AUTOSAR XML (schema 4-0-3)
standard types defined: Boolean, UInt16, UInt32
package /AUTOSAR_Platform/DataConstrs
  range DC_Boolean: raw 0..1
  range DC_UInt16: raw 0..65535
package /PATAC/MSM/ComponentTypes
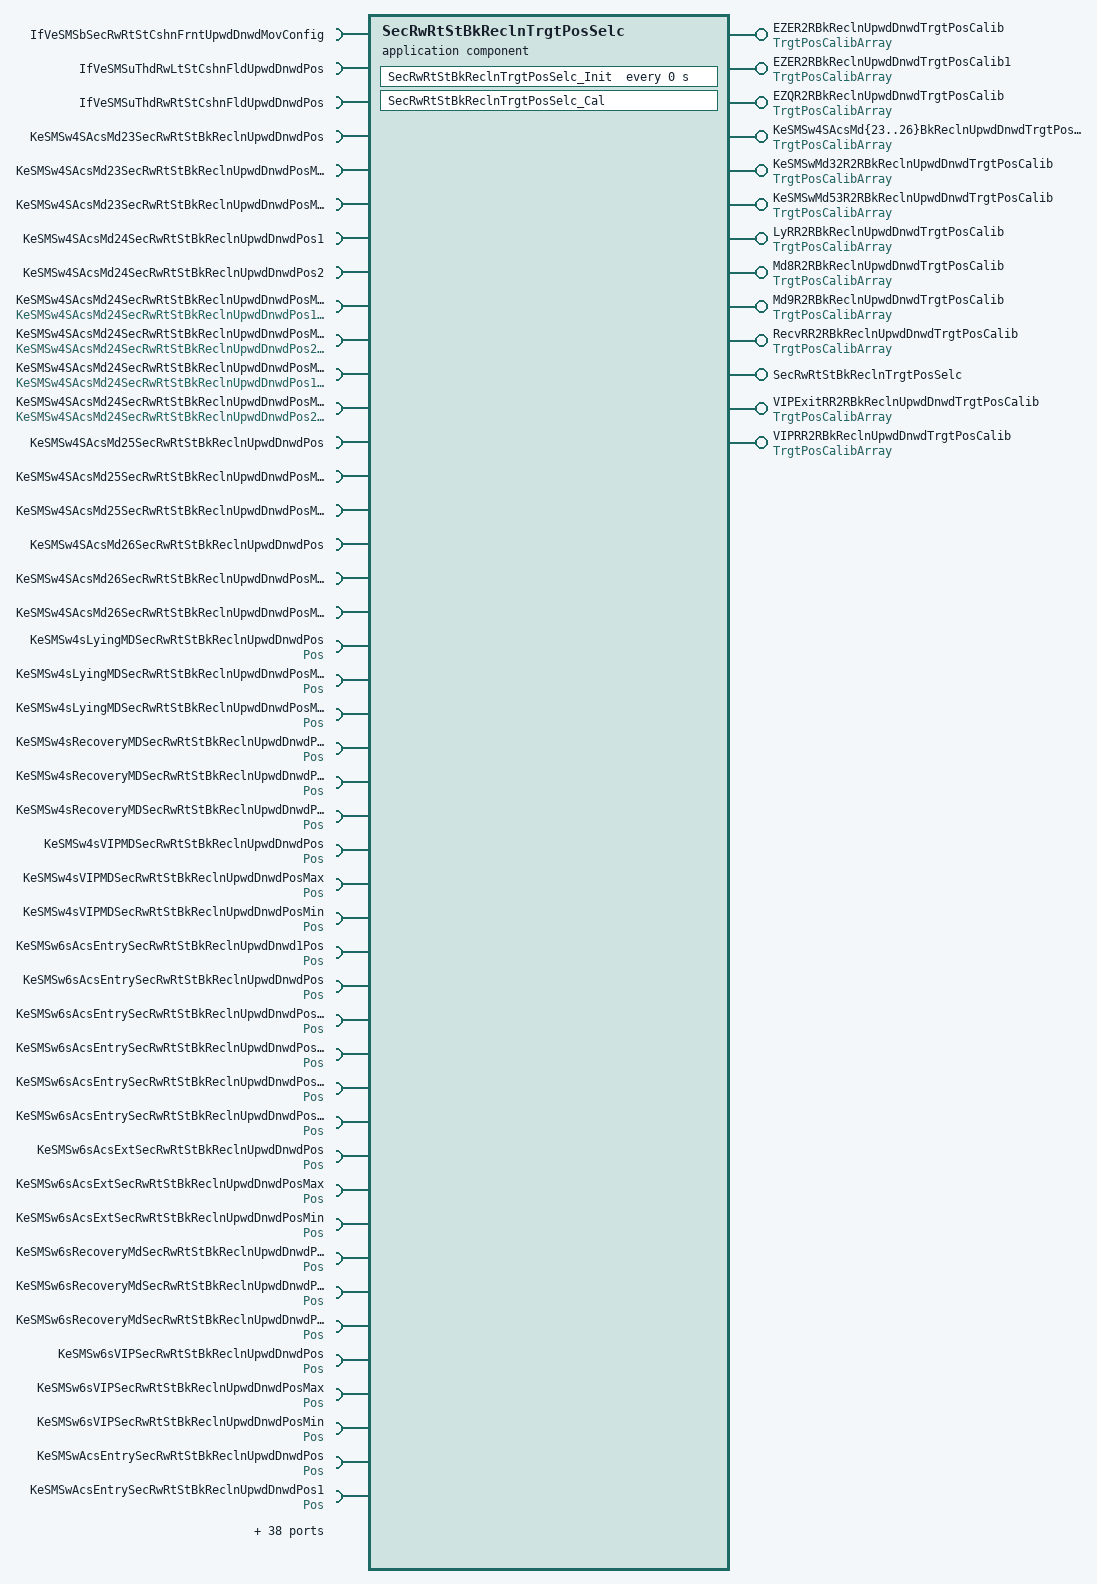
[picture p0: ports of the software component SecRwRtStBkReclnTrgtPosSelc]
  application sw component type SecRwRtStBkReclnTrgtPosSelc
    16 x provide port:
      EZER2RBkReclnUpwdDnwdTrgtPosCalib: nonqueued-sender-com-spec{data-element=TrgtPosArray, init-value=[4095, 4095, 4095]}, provided-interface=TrgtPosCalibArray
      EZER2RBkReclnUpwdDnwdTrgtPosCalib1: nonqueued-sender-com-spec{data-element=TrgtPosArray, init-value=[4095, 4095, 4095]}, provided-interface=TrgtPosCalibArray
      EZQR2RBkReclnUpwdDnwdTrgtPosCalib: nonqueued-sender-com-spec{data-element=TrgtPosArray, init-value=[4095, 4095, 4095]}, provided-interface=TrgtPosCalibArray
      KeSMSw4SAcsMd{23..26}BkReclnUpwdDnwdTrgtPosCalib: nonqueued-sender-com-spec{data-element=TrgtPosArray, init-value=[4095, 4095, 4095]}, provided-interface=TrgtPosCalibArray
      KeSMSwMd32R2RBkReclnUpwdDnwdTrgtPosCalib: nonqueued-sender-com-spec{data-element=TrgtPosArray, init-value=[4095, 4095, 4095]}, provided-interface=TrgtPosCalibArray
      KeSMSwMd53R2RBkReclnUpwdDnwdTrgtPosCalib: nonqueued-sender-com-spec{data-element=TrgtPosArray, init-value=[4095, 4095, 4095]}, provided-interface=TrgtPosCalibArray
      LyRR2RBkReclnUpwdDnwdTrgtPosCalib: nonqueued-sender-com-spec{data-element=TrgtPosArray, init-value=[4095, 4095, 4095]}, provided-interface=TrgtPosCalibArray
      Md8R2RBkReclnUpwdDnwdTrgtPosCalib: nonqueued-sender-com-spec{data-element=TrgtPosArray, init-value=[4095, 4095, 4095]}, provided-interface=TrgtPosCalibArray
      Md9R2RBkReclnUpwdDnwdTrgtPosCalib: nonqueued-sender-com-spec{data-element=TrgtPosArray, init-value=[4095, 4095, 4095]}, provided-interface=TrgtPosCalibArray
      RecvRR2RBkReclnUpwdDnwdTrgtPosCalib: nonqueued-sender-com-spec{data-element=TrgtPosArray, init-value=[4095, 4095, 4095]}, provided-interface=TrgtPosCalibArray
      SecRwRtStBkReclnTrgtPosSelc: server-com-spec{operation=Cal, queue-length=1}, provided-interface=SecRwRtStBkReclnTrgtPosSelc
      VIPExitRR2RBkReclnUpwdDnwdTrgtPosCalib: nonqueued-sender-com-spec{data-element=TrgtPosArray, init-value=[4095, 4095, 4095]}, provided-interface=TrgtPosCalibArray
      VIPRR2RBkReclnUpwdDnwdTrgtPosCalib: nonqueued-sender-com-spec{data-element=TrgtPosArray, init-value=[4095, 4095, 4095]}, provided-interface=TrgtPosCalibArray
    82 x require port:
      IfVeSMSbSecRwRtStCshnFrntUpwdDnwdMovConfig: nonqueued-receiver-com-spec{data-element=IfVeSMSbSecRwRtStCshnFrntUpwdDnwdMovConfig/Val, filter=data-filter-type=ALWAYS, init-value=0}, required-interface=IfVeSMSbSecRwRtStCshnFrntUpwdDnwdMovConfig
      IfVeSMSuThdRwLtStCshnFldUpwdDnwdPos: nonqueued-receiver-com-spec{data-element=IfVeSMSuThdRwLtStCshnFldUpwdDnwdPos/Val, filter=data-filter-type=ALWAYS, init-value=0}, required-interface=IfVeSMSuThdRwLtStCshnFldUpwdDnwdPos
      IfVeSMSuThdRwRtStCshnFldUpwdDnwdPos: nonqueued-receiver-com-spec{data-element=IfVeSMSuThdRwRtStCshnFldUpwdDnwdPos/Val, filter=data-filter-type=ALWAYS, init-value=0}, required-interface=IfVeSMSuThdRwRtStCshnFldUpwdDnwdPos
      KeSMSw4SAcsMd23SecRwRtStBkReclnUpwdDnwdPos: parameter-require-com-spec{init-value=0, parameter=KeSMSw4SAcsMd23SecRwRtStBkReclnUpwdDnwdPos/Val}, required-interface=KeSMSw4SAcsMd23SecRwRtStBkReclnUpwdDnwdPos
      KeSMSw4SAcsMd23SecRwRtStBkReclnUpwdDnwdPosMax: parameter-require-com-spec{init-value=0, parameter=KeSMSw4SAcsMd23SecRwRtStBkReclnUpwdDnwdPosMax/Val}, required-interface=KeSMSw4SAcsMd23SecRwRtStBkReclnUpwdDnwdPosMax
      KeSMSw4SAcsMd23SecRwRtStBkReclnUpwdDnwdPosMin: parameter-require-com-spec{init-value=0, parameter=KeSMSw4SAcsMd23SecRwRtStBkReclnUpwdDnwdPosMin/Val}, required-interface=KeSMSw4SAcsMd23SecRwRtStBkReclnUpwdDnwdPosMin
      KeSMSw4SAcsMd24SecRwRtStBkReclnUpwdDnwdPos1: parameter-require-com-spec{init-value=0, parameter=KeSMSw4SAcsMd24SecRwRtStBkReclnUpwdDnwdPos1/Val}, required-interface=KeSMSw4SAcsMd24SecRwRtStBkReclnUpwdDnwdPos1
      KeSMSw4SAcsMd24SecRwRtStBkReclnUpwdDnwdPos2: parameter-require-com-spec{init-value=0, parameter=KeSMSw4SAcsMd24SecRwRtStBkReclnUpwdDnwdPos2/Val}, required-interface=KeSMSw4SAcsMd24SecRwRtStBkReclnUpwdDnwdPos2
      KeSMSw4SAcsMd24SecRwRtStBkReclnUpwdDnwdPosMax1: parameter-require-com-spec{init-value=0, parameter=KeSMSw4SAcsMd24SecRwRtStBkReclnUpwdDnwdPos1Max/Val}, required-interface=KeSMSw4SAcsMd24SecRwRtStBkReclnUpwdDnwdPos1Max
      KeSMSw4SAcsMd24SecRwRtStBkReclnUpwdDnwdPosMax2: parameter-require-com-spec{init-value=0, parameter=KeSMSw4SAcsMd24SecRwRtStBkReclnUpwdDnwdPos2Max/Val}, required-interface=KeSMSw4SAcsMd24SecRwRtStBkReclnUpwdDnwdPos2Max
      KeSMSw4SAcsMd24SecRwRtStBkReclnUpwdDnwdPosMin1: parameter-require-com-spec{init-value=0, parameter=KeSMSw4SAcsMd24SecRwRtStBkReclnUpwdDnwdPos1Min/Val}, required-interface=KeSMSw4SAcsMd24SecRwRtStBkReclnUpwdDnwdPos1Min
      KeSMSw4SAcsMd24SecRwRtStBkReclnUpwdDnwdPosMin2: parameter-require-com-spec{init-value=0, parameter=KeSMSw4SAcsMd24SecRwRtStBkReclnUpwdDnwdPos2Min/Val}, required-interface=KeSMSw4SAcsMd24SecRwRtStBkReclnUpwdDnwdPos2Min
      KeSMSw4SAcsMd25SecRwRtStBkReclnUpwdDnwdPos: parameter-require-com-spec{init-value=0, parameter=KeSMSw4SAcsMd25SecRwRtStBkReclnUpwdDnwdPos/Val}, required-interface=KeSMSw4SAcsMd25SecRwRtStBkReclnUpwdDnwdPos
      KeSMSw4SAcsMd25SecRwRtStBkReclnUpwdDnwdPosMax: parameter-require-com-spec{init-value=0, parameter=KeSMSw4SAcsMd25SecRwRtStBkReclnUpwdDnwdPosMax/Val}, required-interface=KeSMSw4SAcsMd25SecRwRtStBkReclnUpwdDnwdPosMax
      KeSMSw4SAcsMd25SecRwRtStBkReclnUpwdDnwdPosMin: parameter-require-com-spec{init-value=0, parameter=KeSMSw4SAcsMd25SecRwRtStBkReclnUpwdDnwdPosMin/Val}, required-interface=KeSMSw4SAcsMd25SecRwRtStBkReclnUpwdDnwdPosMin
      KeSMSw4SAcsMd26SecRwRtStBkReclnUpwdDnwdPos: parameter-require-com-spec{init-value=0, parameter=KeSMSw4SAcsMd26SecRwRtStBkReclnUpwdDnwdPos/Val}, required-interface=KeSMSw4SAcsMd26SecRwRtStBkReclnUpwdDnwdPos
      KeSMSw4SAcsMd26SecRwRtStBkReclnUpwdDnwdPosMax: parameter-require-com-spec{init-value=0, parameter=KeSMSw4SAcsMd26SecRwRtStBkReclnUpwdDnwdPosMax/Val}, required-interface=KeSMSw4SAcsMd26SecRwRtStBkReclnUpwdDnwdPosMax
      KeSMSw4SAcsMd26SecRwRtStBkReclnUpwdDnwdPosMin: parameter-require-com-spec{init-value=0, parameter=KeSMSw4SAcsMd26SecRwRtStBkReclnUpwdDnwdPosMin/Val}, required-interface=KeSMSw4SAcsMd26SecRwRtStBkReclnUpwdDnwdPosMin
      KeSMSw4sLyingMDSecRwRtStBkReclnUpwdDnwdPos: parameter-require-com-spec{init-value=0, parameter=Pos/Val}, required-interface=Pos
      KeSMSw4sLyingMDSecRwRtStBkReclnUpwdDnwdPosMax: parameter-require-com-spec{init-value=0, parameter=Pos/Val}, required-interface=Pos
      KeSMSw4sLyingMDSecRwRtStBkReclnUpwdDnwdPosMin: parameter-require-com-spec{init-value=0, parameter=Pos/Val}, required-interface=Pos
      KeSMSw4sRecoveryMDSecRwRtStBkReclnUpwdDnwdPos: parameter-require-com-spec{init-value=0, parameter=Pos/Val}, required-interface=Pos
      KeSMSw4sRecoveryMDSecRwRtStBkReclnUpwdDnwdPosMax: parameter-require-com-spec{init-value=0, parameter=Pos/Val}, required-interface=Pos
      KeSMSw4sRecoveryMDSecRwRtStBkReclnUpwdDnwdPosMin: parameter-require-com-spec{init-value=0, parameter=Pos/Val}, required-interface=Pos
      KeSMSw4sVIPMDSecRwRtStBkReclnUpwdDnwdPos: parameter-require-com-spec{init-value=0, parameter=Pos/Val}, required-interface=Pos
      KeSMSw4sVIPMDSecRwRtStBkReclnUpwdDnwdPosMax: parameter-require-com-spec{init-value=0, parameter=Pos/Val}, required-interface=Pos
      KeSMSw4sVIPMDSecRwRtStBkReclnUpwdDnwdPosMin: parameter-require-com-spec{init-value=0, parameter=Pos/Val}, required-interface=Pos
      KeSMSw6sAcsEntrySecRwRtStBkReclnUpwdDnwd1Pos: parameter-require-com-spec{init-value=1280, parameter=Pos/Val}, required-interface=Pos
      KeSMSw6sAcsEntrySecRwRtStBkReclnUpwdDnwdPos: parameter-require-com-spec{init-value=1280, parameter=Pos/Val}, required-interface=Pos
      KeSMSw6sAcsEntrySecRwRtStBkReclnUpwdDnwdPos1Max: parameter-require-com-spec{init-value=1280, parameter=Pos/Val}, required-interface=Pos
      KeSMSw6sAcsEntrySecRwRtStBkReclnUpwdDnwdPos1Min: parameter-require-com-spec{init-value=0, parameter=Pos/Val}, required-interface=Pos
      KeSMSw6sAcsEntrySecRwRtStBkReclnUpwdDnwdPosMax: parameter-require-com-spec{init-value=1280, parameter=Pos/Val}, required-interface=Pos
      KeSMSw6sAcsEntrySecRwRtStBkReclnUpwdDnwdPosMin: parameter-require-com-spec{init-value=0, parameter=Pos/Val}, required-interface=Pos
      KeSMSw6sAcsExtSecRwRtStBkReclnUpwdDnwdPos: parameter-require-com-spec{init-value=1280, parameter=Pos/Val}, required-interface=Pos
      KeSMSw6sAcsExtSecRwRtStBkReclnUpwdDnwdPosMax: parameter-require-com-spec{init-value=1280, parameter=Pos/Val}, required-interface=Pos
      KeSMSw6sAcsExtSecRwRtStBkReclnUpwdDnwdPosMin: parameter-require-com-spec{init-value=0, parameter=Pos/Val}, required-interface=Pos
      KeSMSw6sRecoveryMdSecRwRtStBkReclnUpwdDnwdPos: parameter-require-com-spec{init-value=1268, parameter=Pos/Val}, required-interface=Pos
      KeSMSw6sRecoveryMdSecRwRtStBkReclnUpwdDnwdPosMax: parameter-require-com-spec{init-value=1268, parameter=Pos/Val}, required-interface=Pos
      KeSMSw6sRecoveryMdSecRwRtStBkReclnUpwdDnwdPosMin: parameter-require-com-spec{init-value=0, parameter=Pos/Val}, required-interface=Pos
      KeSMSw6sVIPSecRwRtStBkReclnUpwdDnwdPos: parameter-require-com-spec{init-value=1960, parameter=Pos/Val}, required-interface=Pos
      KeSMSw6sVIPSecRwRtStBkReclnUpwdDnwdPosMax: parameter-require-com-spec{init-value=40, parameter=Pos/Val}, required-interface=Pos
      KeSMSw6sVIPSecRwRtStBkReclnUpwdDnwdPosMin: parameter-require-com-spec{init-value=1960, parameter=Pos/Val}, required-interface=Pos
      KeSMSwAcsEntrySecRwRtStBkReclnUpwdDnwdPos: parameter-require-com-spec{init-value=1280, parameter=Pos/Val}, required-interface=Pos
      KeSMSwAcsEntrySecRwRtStBkReclnUpwdDnwdPos1: parameter-require-com-spec{init-value=1280, parameter=Pos/Val}, required-interface=Pos
      KeSMSwAcsEntrySecRwRtStBkReclnUpwdDnwdPos1Max: parameter-require-com-spec{init-value=1280, parameter=Pos/Val}, required-interface=Pos
      KeSMSwAcsEntrySecRwRtStBkReclnUpwdDnwdPos1Min: parameter-require-com-spec{init-value=0, parameter=Pos/Val}, required-interface=Pos
      KeSMSwAcsEntrySecRwRtStBkReclnUpwdDnwdPosMax: parameter-require-com-spec{init-value=1280, parameter=Pos/Val}, required-interface=Pos
      KeSMSwAcsEntrySecRwRtStBkReclnUpwdDnwdPosMin: parameter-require-com-spec{init-value=0, parameter=Pos/Val}, required-interface=Pos
      KeSMSwAcsExtSecRwRtStBkReclnUpwdDnwdPos: parameter-require-com-spec{init-value=1280, parameter=Pos/Val}, required-interface=Pos
      KeSMSwAcsExtSecRwRtStBkReclnUpwdDnwdPosMax: parameter-require-com-spec{init-value=1280, parameter=Pos/Val}, required-interface=Pos
      KeSMSwAcsExtSecRwRtStBkReclnUpwdDnwdPosMin: parameter-require-com-spec{init-value=0, parameter=Pos/Val}, required-interface=Pos
      KeSMSwAcsMd32SecRwRtStBkReclnUpwdDnwdPos: parameter-require-com-spec{init-value=0, parameter=Pos/Val}, required-interface=Pos
      KeSMSwAcsMd32SecRwRtStBkReclnUpwdDnwdPos1: parameter-require-com-spec{init-value=0, parameter=Pos/Val}, required-interface=Pos
      KeSMSwAcsMd32SecRwRtStBkReclnUpwdDnwdPos1Max: parameter-require-com-spec{init-value=0, parameter=Pos/Val}, required-interface=Pos
      KeSMSwAcsMd32SecRwRtStBkReclnUpwdDnwdPos1Min: parameter-require-com-spec{init-value=0, parameter=Pos/Val}, required-interface=Pos
      KeSMSwAcsMd32SecRwRtStBkReclnUpwdDnwdPosMax: parameter-require-com-spec{init-value=0, parameter=Pos/Val}, required-interface=Pos
      KeSMSwAcsMd32SecRwRtStBkReclnUpwdDnwdPosMin: parameter-require-com-spec{init-value=0, parameter=Pos/Val}, required-interface=Pos
      KeSMSwAcsMd53SecRwRtStBkReclnUpwdDnwdPos: parameter-require-com-spec{init-value=0, parameter=Pos/Val}, required-interface=Pos
      KeSMSwAcsMd53SecRwRtStBkReclnUpwdDnwdPos1: parameter-require-com-spec{init-value=0, parameter=Pos/Val}, required-interface=Pos
      KeSMSwAcsMd53SecRwRtStBkReclnUpwdDnwdPos1Max: parameter-require-com-spec{init-value=0, parameter=Pos/Val}, required-interface=Pos
      KeSMSwAcsMd53SecRwRtStBkReclnUpwdDnwdPos1Min: parameter-require-com-spec{init-value=0, parameter=Pos/Val}, required-interface=Pos
      KeSMSwAcsMd53SecRwRtStBkReclnUpwdDnwdPosMax: parameter-require-com-spec{init-value=0, parameter=Pos/Val}, required-interface=Pos
      KeSMSwAcsMd53SecRwRtStBkReclnUpwdDnwdPosMin: parameter-require-com-spec{init-value=0, parameter=Pos/Val}, required-interface=Pos
      KeSMSwAcsMd8SecRwRtStBkReclnUpwdDnwdPos: parameter-require-com-spec{init-value=0, parameter=Pos/Val}, required-interface=Pos
      KeSMSwAcsMd8SecRwRtStBkReclnUpwdDnwdPosMax: parameter-require-com-spec{init-value=0, parameter=Pos/Val}, required-interface=Pos
      KeSMSwAcsMd8SecRwRtStBkReclnUpwdDnwdPosMin: parameter-require-com-spec{init-value=0, parameter=Pos/Val}, required-interface=Pos
      KeSMSwAcsMd9SecRwRtStBkReclnUpwdDnwdPos: parameter-require-com-spec{init-value=0, parameter=Pos/Val}, required-interface=Pos
      KeSMSwAcsMd9SecRwRtStBkReclnUpwdDnwdPosMax: parameter-require-com-spec{init-value=0, parameter=Pos/Val}, required-interface=Pos
      KeSMSwAcsMd9SecRwRtStBkReclnUpwdDnwdPosMin: parameter-require-com-spec{init-value=0, parameter=Pos/Val}, required-interface=Pos
      KeSMSwRecoveryMdSecRwRtStBkReclnUpwdDnwdPos: parameter-require-com-spec{init-value=1268, parameter=Pos/Val}, required-interface=Pos
      KeSMSwRecoveryMdSecRwRtStBkReclnUpwdDnwdPosMax: parameter-require-com-spec{init-value=1268, parameter=Pos/Val}, required-interface=Pos
      KeSMSwRecoveryMdSecRwRtStBkReclnUpwdDnwdPosMin: parameter-require-com-spec{init-value=0, parameter=Pos/Val}, required-interface=Pos
      KeSMSwVIPSecRwRtStBkReclnUpwdDnwdPos: parameter-require-com-spec{init-value=1960, parameter=Pos/Val}, required-interface=Pos
      KeSMSwVIPSecRwRtStBkReclnUpwdDnwdPosMax: parameter-require-com-spec{init-value=40, parameter=Pos/Val}, required-interface=Pos
      KeSMSwVIPSecRwRtStBkReclnUpwdDnwdPosMin: parameter-require-com-spec{init-value=1960, parameter=Pos/Val}, required-interface=Pos
      modestate32: nonqueued-receiver-com-spec{data-element=modestate32/Val, filter=data-filter-type=ALWAYS, init-value=0}, required-interface=modestate32
      R2RBkReclinFirstStepPassFlg: nonqueued-receiver-com-spec{data-element=R2RBkReclinFirstStepPassFlg/Val, filter=data-filter-type=ALWAYS, init-value=0}, required-interface=R2RBkReclinFirstStepPassFlg
      R2RMdSeatOccupied: nonqueued-receiver-com-spec{data-element=MdSeatOccupied/Val, filter=data-filter-type=ALWAYS, init-value=0}, required-interface=MdSeatOccupied
      StNumFlg: required-interface=StNumFlg
        required-com-specs:
          data-element=Is4s, filter=data-filter-type=ALWAYS, init-value=0
          data-element=Is6s, filter=data-filter-type=ALWAYS, init-value=0
          data-element=Is6s7s, filter=data-filter-type=ALWAYS, init-value=0
          data-element=Is7s, filter=data-filter-type=ALWAYS, init-value=0
      ThdRwRtStCshnFldStgDone: nonqueued-receiver-com-spec{data-element=StgDone/Val, filter=data-filter-type=ALWAYS, init-value=0}, required-interface=StgDone
      VIPR557TrgtPos: required-com-specs=[VIPR557TrgtPos/Get, VIPR557TrgtPos/Set], required-interface=VIPR557TrgtPos
      VIPRExit557TrgtPos: required-com-specs=[VIPRExit557TrgtPos/Get, VIPRExit557TrgtPos/Set], required-interface=VIPRExit557TrgtPos
    behavior SecRwRtStBkReclnTrgtPosSelc_InternalBehavior
      operation invoked event OIT_SecRwRtStBkReclnTrgtPosSelc_Cal_SecRwRtStBkReclnTrgtPosSelc_Cal: start-on-event=SecRwRtStBkReclnTrgtPosSelc_Cal, operation=SecRwRtStBkReclnTrgtPosSelc.Cal
      timing event SecRwRtStBkReclnTrgtPosSelc_InitEvent: start-on-event=SecRwRtStBkReclnTrgtPosSelc_Init, period=0
      runnable SecRwRtStBkReclnTrgtPosSelc_Cal
        data-receive-point-by-arguments:
          11 x access:
            REC_IfVeSMSbSecRwRtStCshnFrntUpwdDnwdMovConfig_Val: accessed-variable=IfVeSMSbSecRwRtStCshnFrntUpwdDnwdMovConfig.Val
            REC_IfVeSMSuThdRwLtStCshnFldUpwdDnwdPos_Val: accessed-variable=IfVeSMSuThdRwLtStCshnFldUpwdDnwdPos.Val
            REC_IfVeSMSuThdRwRtStCshnFldUpwdDnwdPos_Val: accessed-variable=IfVeSMSuThdRwRtStCshnFldUpwdDnwdPos.Val
            REC_modestate32_Val: accessed-variable=modestate32.Val
            REC_R2RBkReclinFirstStepPassFlg_Val: accessed-variable=R2RBkReclinFirstStepPassFlg.Val
            REC_R2RMdSeatOccupied_Val: accessed-variable=R2RMdSeatOccupied.Val
            REC_StNumFlg_Is4s: accessed-variable=StNumFlg.Is4s
            REC_StNumFlg_Is6s: accessed-variable=StNumFlg.Is6s
            REC_StNumFlg_Is6s7s: accessed-variable=StNumFlg.Is6s7s
            REC_StNumFlg_Is7s: accessed-variable=StNumFlg.Is7s
            REC_ThdRwRtStCshnFldStgDone_Val: accessed-variable=ThdRwRtStCshnFldStgDone.Val
        data-send-points:
          15 x access:
            SEND_EZER2RBkReclnUpwdDnwdTrgtPosCalib_TrgtPosArray: accessed-variable=EZER2RBkReclnUpwdDnwdTrgtPosCalib.TrgtPosArray
            SEND_EZER2RBkReclnUpwdDnwdTrgtPosCalib1_TrgtPosArray: accessed-variable=EZER2RBkReclnUpwdDnwdTrgtPosCalib1.TrgtPosArray
            SEND_EZQR2RBkReclnUpwdDnwdTrgtPosCalib_TrgtPosArray: accessed-variable=EZQR2RBkReclnUpwdDnwdTrgtPosCalib.TrgtPosArray
            SEND_KeSMSw4SAcsMd{23..26}BkReclnUpwdDnwdTrgtPosCalib_TrgtPosArray: accessed-variable=KeSMSw4SAcsMd{23..26}BkReclnUpwdDnwdTrgtPosCalib.TrgtPosArray
            SEND_KeSMSwMd32R2RBkReclnUpwdDnwdTrgtPosCalib_TrgtPosArray: accessed-variable=KeSMSwMd32R2RBkReclnUpwdDnwdTrgtPosCalib.TrgtPosArray
            SEND_KeSMSwMd53R2RBkReclnUpwdDnwdTrgtPosCalib_TrgtPosArray: accessed-variable=KeSMSwMd53R2RBkReclnUpwdDnwdTrgtPosCalib.TrgtPosArray
            SEND_LyRR2RBkReclnUpwdDnwdTrgtPosCalib_TrgtPosArray: accessed-variable=LyRR2RBkReclnUpwdDnwdTrgtPosCalib.TrgtPosArray
            SEND_Md8R2RBkReclnUpwdDnwdTrgtPosCalib_TrgtPosArray: accessed-variable=Md8R2RBkReclnUpwdDnwdTrgtPosCalib.TrgtPosArray
            SEND_Md9R2RBkReclnUpwdDnwdTrgtPosCalib_TrgtPosArray: accessed-variable=Md9R2RBkReclnUpwdDnwdTrgtPosCalib.TrgtPosArray
            SEND_RecvRR2RBkReclnUpwdDnwdTrgtPosCalib_TrgtPosArray: accessed-variable=RecvRR2RBkReclnUpwdDnwdTrgtPosCalib.TrgtPosArray
            SEND_VIPExitRR2RBkReclnUpwdDnwdTrgtPosCalib_TrgtPosArray: accessed-variable=VIPExitRR2RBkReclnUpwdDnwdTrgtPosCalib.TrgtPosArray
            SEND_VIPRR2RBkReclnUpwdDnwdTrgtPosCalib_TrgtPosArray: accessed-variable=VIPRR2RBkReclnUpwdDnwdTrgtPosCalib.TrgtPosArray
        72 x parameter access:
          PA_KeSMSw4SAcsMd23SecRwRtStBkReclnUpwdDnwdPos_Val: accessed-parameter=KeSMSw4SAcsMd23SecRwRtStBkReclnUpwdDnwdPos.Val
          PA_KeSMSw4SAcsMd23SecRwRtStBkReclnUpwdDnwdPosMax_Val: accessed-parameter=KeSMSw4SAcsMd23SecRwRtStBkReclnUpwdDnwdPosMax.Val
          PA_KeSMSw4SAcsMd23SecRwRtStBkReclnUpwdDnwdPosMin_Val: accessed-parameter=KeSMSw4SAcsMd23SecRwRtStBkReclnUpwdDnwdPosMin.Val
          PA_KeSMSw4SAcsMd24SecRwRtStBkReclnUpwdDnwdPos1_Val: accessed-parameter=KeSMSw4SAcsMd24SecRwRtStBkReclnUpwdDnwdPos1.Val
          PA_KeSMSw4SAcsMd24SecRwRtStBkReclnUpwdDnwdPos2_Val: accessed-parameter=KeSMSw4SAcsMd24SecRwRtStBkReclnUpwdDnwdPos2.Val
          PA_KeSMSw4SAcsMd24SecRwRtStBkReclnUpwdDnwdPosMax1_Val: accessed-parameter=KeSMSw4SAcsMd24SecRwRtStBkReclnUpwdDnwdPosMax1.Val
          PA_KeSMSw4SAcsMd24SecRwRtStBkReclnUpwdDnwdPosMax2_Val: accessed-parameter=KeSMSw4SAcsMd24SecRwRtStBkReclnUpwdDnwdPosMax2.Val
          PA_KeSMSw4SAcsMd24SecRwRtStBkReclnUpwdDnwdPosMin1_Val: accessed-parameter=KeSMSw4SAcsMd24SecRwRtStBkReclnUpwdDnwdPosMin1.Val
          PA_KeSMSw4SAcsMd24SecRwRtStBkReclnUpwdDnwdPosMin2_Val: accessed-parameter=KeSMSw4SAcsMd24SecRwRtStBkReclnUpwdDnwdPosMin2.Val
          PA_KeSMSw4SAcsMd25SecRwRtStBkReclnUpwdDnwdPos_Val: accessed-parameter=KeSMSw4SAcsMd25SecRwRtStBkReclnUpwdDnwdPos.Val
          PA_KeSMSw4SAcsMd25SecRwRtStBkReclnUpwdDnwdPosMax_Val: accessed-parameter=KeSMSw4SAcsMd25SecRwRtStBkReclnUpwdDnwdPosMax.Val
          PA_KeSMSw4SAcsMd25SecRwRtStBkReclnUpwdDnwdPosMin_Val: accessed-parameter=KeSMSw4SAcsMd25SecRwRtStBkReclnUpwdDnwdPosMin.Val
          PA_KeSMSw4SAcsMd26SecRwRtStBkReclnUpwdDnwdPos_Val: accessed-parameter=KeSMSw4SAcsMd26SecRwRtStBkReclnUpwdDnwdPos.Val
          PA_KeSMSw4SAcsMd26SecRwRtStBkReclnUpwdDnwdPosMax_Val: accessed-parameter=KeSMSw4SAcsMd26SecRwRtStBkReclnUpwdDnwdPosMax.Val
          PA_KeSMSw4SAcsMd26SecRwRtStBkReclnUpwdDnwdPosMin_Val: accessed-parameter=KeSMSw4SAcsMd26SecRwRtStBkReclnUpwdDnwdPosMin.Val
          PA_KeSMSw4sLyingMDSecRwRtStBkReclnUpwdDnwdPos_Val: accessed-parameter=KeSMSw4sLyingMDSecRwRtStBkReclnUpwdDnwdPos.Val
          PA_KeSMSw4sLyingMDSecRwRtStBkReclnUpwdDnwdPosMax_Val: accessed-parameter=KeSMSw4sLyingMDSecRwRtStBkReclnUpwdDnwdPosMax.Val
          PA_KeSMSw4sLyingMDSecRwRtStBkReclnUpwdDnwdPosMin_Val: accessed-parameter=KeSMSw4sLyingMDSecRwRtStBkReclnUpwdDnwdPosMin.Val
          PA_KeSMSw4sRecoveryMDSecRwRtStBkReclnUpwdDnwdPos_Val: accessed-parameter=KeSMSw4sRecoveryMDSecRwRtStBkReclnUpwdDnwdPos.Val
          PA_KeSMSw4sRecoveryMDSecRwRtStBkReclnUpwdDnwdPosMax_Val: accessed-parameter=KeSMSw4sRecoveryMDSecRwRtStBkReclnUpwdDnwdPosMax.Val
          PA_KeSMSw4sRecoveryMDSecRwRtStBkReclnUpwdDnwdPosMin_Val: accessed-parameter=KeSMSw4sRecoveryMDSecRwRtStBkReclnUpwdDnwdPosMin.Val
          PA_KeSMSw4sVIPMDSecRwRtStBkReclnUpwdDnwdPos_Val: accessed-parameter=KeSMSw4sVIPMDSecRwRtStBkReclnUpwdDnwdPos.Val
          PA_KeSMSw4sVIPMDSecRwRtStBkReclnUpwdDnwdPosMax_Val: accessed-parameter=KeSMSw4sVIPMDSecRwRtStBkReclnUpwdDnwdPosMax.Val
          PA_KeSMSw4sVIPMDSecRwRtStBkReclnUpwdDnwdPosMin_Val: accessed-parameter=KeSMSw4sVIPMDSecRwRtStBkReclnUpwdDnwdPosMin.Val
          PA_KeSMSw6sAcsEntrySecRwRtStBkReclnUpwdDnwd1Pos_Val: accessed-parameter=KeSMSw6sAcsEntrySecRwRtStBkReclnUpwdDnwd1Pos.Val
          PA_KeSMSw6sAcsEntrySecRwRtStBkReclnUpwdDnwdPos_Val: accessed-parameter=KeSMSw6sAcsEntrySecRwRtStBkReclnUpwdDnwdPos.Val
          PA_KeSMSw6sAcsEntrySecRwRtStBkReclnUpwdDnwdPos1Max_Val: accessed-parameter=KeSMSw6sAcsEntrySecRwRtStBkReclnUpwdDnwdPos1Max.Val
          PA_KeSMSw6sAcsEntrySecRwRtStBkReclnUpwdDnwdPos1Min_Val: accessed-parameter=KeSMSw6sAcsEntrySecRwRtStBkReclnUpwdDnwdPos1Min.Val
          PA_KeSMSw6sAcsEntrySecRwRtStBkReclnUpwdDnwdPosMax_Val: accessed-parameter=KeSMSw6sAcsEntrySecRwRtStBkReclnUpwdDnwdPosMax.Val
          PA_KeSMSw6sAcsEntrySecRwRtStBkReclnUpwdDnwdPosMin_Val: accessed-parameter=KeSMSw6sAcsEntrySecRwRtStBkReclnUpwdDnwdPosMin.Val
          PA_KeSMSw6sAcsExtSecRwRtStBkReclnUpwdDnwdPos_Val: accessed-parameter=KeSMSw6sAcsExtSecRwRtStBkReclnUpwdDnwdPos.Val
          PA_KeSMSw6sAcsExtSecRwRtStBkReclnUpwdDnwdPosMax_Val: accessed-parameter=KeSMSw6sAcsExtSecRwRtStBkReclnUpwdDnwdPosMax.Val
          PA_KeSMSw6sAcsExtSecRwRtStBkReclnUpwdDnwdPosMin_Val: accessed-parameter=KeSMSw6sAcsExtSecRwRtStBkReclnUpwdDnwdPosMin.Val
          PA_KeSMSw6sRecoveryMdSecRwRtStBkReclnUpwdDnwdPos_Val: accessed-parameter=KeSMSw6sRecoveryMdSecRwRtStBkReclnUpwdDnwdPos.Val
          PA_KeSMSw6sRecoveryMdSecRwRtStBkReclnUpwdDnwdPosMax_Val: accessed-parameter=KeSMSw6sRecoveryMdSecRwRtStBkReclnUpwdDnwdPosMax.Val
          PA_KeSMSw6sRecoveryMdSecRwRtStBkReclnUpwdDnwdPosMin_Val: accessed-parameter=KeSMSw6sRecoveryMdSecRwRtStBkReclnUpwdDnwdPosMin.Val
          PA_KeSMSw6sVIPSecRwRtStBkReclnUpwdDnwdPos_Val: accessed-parameter=KeSMSw6sVIPSecRwRtStBkReclnUpwdDnwdPos.Val
          PA_KeSMSw6sVIPSecRwRtStBkReclnUpwdDnwdPosMax_Val: accessed-parameter=KeSMSw6sVIPSecRwRtStBkReclnUpwdDnwdPosMax.Val
          PA_KeSMSw6sVIPSecRwRtStBkReclnUpwdDnwdPosMin_Val: accessed-parameter=KeSMSw6sVIPSecRwRtStBkReclnUpwdDnwdPosMin.Val
          PA_KeSMSwAcsEntrySecRwRtStBkReclnUpwdDnwdPos_Val: accessed-parameter=KeSMSwAcsEntrySecRwRtStBkReclnUpwdDnwdPos.Val
          PA_KeSMSwAcsEntrySecRwRtStBkReclnUpwdDnwdPos1_Val: accessed-parameter=KeSMSwAcsEntrySecRwRtStBkReclnUpwdDnwdPos1.Val
          PA_KeSMSwAcsEntrySecRwRtStBkReclnUpwdDnwdPos1Max_Val: accessed-parameter=KeSMSwAcsEntrySecRwRtStBkReclnUpwdDnwdPos1Max.Val
          PA_KeSMSwAcsEntrySecRwRtStBkReclnUpwdDnwdPos1Min_Val: accessed-parameter=KeSMSwAcsEntrySecRwRtStBkReclnUpwdDnwdPos1Min.Val
          PA_KeSMSwAcsEntrySecRwRtStBkReclnUpwdDnwdPosMax_Val: accessed-parameter=KeSMSwAcsEntrySecRwRtStBkReclnUpwdDnwdPosMax.Val
          PA_KeSMSwAcsEntrySecRwRtStBkReclnUpwdDnwdPosMin_Val: accessed-parameter=KeSMSwAcsEntrySecRwRtStBkReclnUpwdDnwdPosMin.Val
          PA_KeSMSwAcsExtSecRwRtStBkReclnUpwdDnwdPos_Val: accessed-parameter=KeSMSwAcsExtSecRwRtStBkReclnUpwdDnwdPos.Val
          PA_KeSMSwAcsExtSecRwRtStBkReclnUpwdDnwdPosMax_Val: accessed-parameter=KeSMSwAcsExtSecRwRtStBkReclnUpwdDnwdPosMax.Val
          PA_KeSMSwAcsExtSecRwRtStBkReclnUpwdDnwdPosMin_Val: accessed-parameter=KeSMSwAcsExtSecRwRtStBkReclnUpwdDnwdPosMin.Val
          PA_KeSMSwAcsMd32SecRwRtStBkReclnUpwdDnwdPos_Val: accessed-parameter=KeSMSwAcsMd32SecRwRtStBkReclnUpwdDnwdPos.Val
          PA_KeSMSwAcsMd32SecRwRtStBkReclnUpwdDnwdPos1_Val: accessed-parameter=KeSMSwAcsMd32SecRwRtStBkReclnUpwdDnwdPos1.Val
          PA_KeSMSwAcsMd32SecRwRtStBkReclnUpwdDnwdPos1Max_Val: accessed-parameter=KeSMSwAcsMd32SecRwRtStBkReclnUpwdDnwdPos1Max.Val
          PA_KeSMSwAcsMd32SecRwRtStBkReclnUpwdDnwdPos1Min_Val: accessed-parameter=KeSMSwAcsMd32SecRwRtStBkReclnUpwdDnwdPos1Min.Val
          PA_KeSMSwAcsMd32SecRwRtStBkReclnUpwdDnwdPosMax_Val: accessed-parameter=KeSMSwAcsMd32SecRwRtStBkReclnUpwdDnwdPosMax.Val
          PA_KeSMSwAcsMd32SecRwRtStBkReclnUpwdDnwdPosMin_Val: accessed-parameter=KeSMSwAcsMd32SecRwRtStBkReclnUpwdDnwdPosMin.Val
          PA_KeSMSwAcsMd53SecRwRtStBkReclnUpwdDnwdPos_Val: accessed-parameter=KeSMSwAcsMd53SecRwRtStBkReclnUpwdDnwdPos.Val
          PA_KeSMSwAcsMd53SecRwRtStBkReclnUpwdDnwdPos1_Val: accessed-parameter=KeSMSwAcsMd53SecRwRtStBkReclnUpwdDnwdPos1.Val
          PA_KeSMSwAcsMd53SecRwRtStBkReclnUpwdDnwdPos1Max_Val: accessed-parameter=KeSMSwAcsMd53SecRwRtStBkReclnUpwdDnwdPos1Max.Val
          PA_KeSMSwAcsMd53SecRwRtStBkReclnUpwdDnwdPos1Min_Val: accessed-parameter=KeSMSwAcsMd53SecRwRtStBkReclnUpwdDnwdPos1Min.Val
          PA_KeSMSwAcsMd53SecRwRtStBkReclnUpwdDnwdPosMax_Val: accessed-parameter=KeSMSwAcsMd53SecRwRtStBkReclnUpwdDnwdPosMax.Val
          PA_KeSMSwAcsMd53SecRwRtStBkReclnUpwdDnwdPosMin_Val: accessed-parameter=KeSMSwAcsMd53SecRwRtStBkReclnUpwdDnwdPosMin.Val
          PA_KeSMSwAcsMd8SecRwRtStBkReclnUpwdDnwdPos_Val: accessed-parameter=KeSMSwAcsMd8SecRwRtStBkReclnUpwdDnwdPos.Val
          PA_KeSMSwAcsMd8SecRwRtStBkReclnUpwdDnwdPosMax_Val: accessed-parameter=KeSMSwAcsMd8SecRwRtStBkReclnUpwdDnwdPosMax.Val
          PA_KeSMSwAcsMd8SecRwRtStBkReclnUpwdDnwdPosMin_Val: accessed-parameter=KeSMSwAcsMd8SecRwRtStBkReclnUpwdDnwdPosMin.Val
          PA_KeSMSwAcsMd9SecRwRtStBkReclnUpwdDnwdPos_Val: accessed-parameter=KeSMSwAcsMd9SecRwRtStBkReclnUpwdDnwdPos.Val
          PA_KeSMSwAcsMd9SecRwRtStBkReclnUpwdDnwdPosMax_Val: accessed-parameter=KeSMSwAcsMd9SecRwRtStBkReclnUpwdDnwdPosMax.Val
          PA_KeSMSwAcsMd9SecRwRtStBkReclnUpwdDnwdPosMin_Val: accessed-parameter=KeSMSwAcsMd9SecRwRtStBkReclnUpwdDnwdPosMin.Val
          PA_KeSMSwRecoveryMdSecRwRtStBkReclnUpwdDnwdPos_Val: accessed-parameter=KeSMSwRecoveryMdSecRwRtStBkReclnUpwdDnwdPos.Val
          PA_KeSMSwRecoveryMdSecRwRtStBkReclnUpwdDnwdPosMax_Val: accessed-parameter=KeSMSwRecoveryMdSecRwRtStBkReclnUpwdDnwdPosMax.Val
          PA_KeSMSwRecoveryMdSecRwRtStBkReclnUpwdDnwdPosMin_Val: accessed-parameter=KeSMSwRecoveryMdSecRwRtStBkReclnUpwdDnwdPosMin.Val
          PA_KeSMSwVIPSecRwRtStBkReclnUpwdDnwdPos_Val: accessed-parameter=KeSMSwVIPSecRwRtStBkReclnUpwdDnwdPos.Val
          PA_KeSMSwVIPSecRwRtStBkReclnUpwdDnwdPosMax_Val: accessed-parameter=KeSMSwVIPSecRwRtStBkReclnUpwdDnwdPosMax.Val
          PA_KeSMSwVIPSecRwRtStBkReclnUpwdDnwdPosMin_Val: accessed-parameter=KeSMSwVIPSecRwRtStBkReclnUpwdDnwdPosMin.Val
        sync call SC_VIPR557TrgtPos_Get: operation=VIPR557TrgtPos.Get, timeout=0
        sync call SC_VIPRExit557TrgtPos_Get: operation=VIPRExit557TrgtPos.Get, timeout=0
      runnable SecRwRtStBkReclnTrgtPosSelc_Init
        72 x parameter access:
          PA_KeSMSw4SAcsMd23SecRwRtStBkReclnUpwdDnwdPos_Val: accessed-parameter=KeSMSw4SAcsMd23SecRwRtStBkReclnUpwdDnwdPos.Val
          PA_KeSMSw4SAcsMd23SecRwRtStBkReclnUpwdDnwdPosMax_Val: accessed-parameter=KeSMSw4SAcsMd23SecRwRtStBkReclnUpwdDnwdPosMax.Val
          PA_KeSMSw4SAcsMd23SecRwRtStBkReclnUpwdDnwdPosMin_Val: accessed-parameter=KeSMSw4SAcsMd23SecRwRtStBkReclnUpwdDnwdPosMin.Val
          PA_KeSMSw4SAcsMd24SecRwRtStBkReclnUpwdDnwdPos1_Val: accessed-parameter=KeSMSw4SAcsMd24SecRwRtStBkReclnUpwdDnwdPos1.Val
          PA_KeSMSw4SAcsMd24SecRwRtStBkReclnUpwdDnwdPos2_Val: accessed-parameter=KeSMSw4SAcsMd24SecRwRtStBkReclnUpwdDnwdPos2.Val
          PA_KeSMSw4SAcsMd24SecRwRtStBkReclnUpwdDnwdPosMax1_Val: accessed-parameter=KeSMSw4SAcsMd24SecRwRtStBkReclnUpwdDnwdPosMax1.Val
          PA_KeSMSw4SAcsMd24SecRwRtStBkReclnUpwdDnwdPosMax2_Val: accessed-parameter=KeSMSw4SAcsMd24SecRwRtStBkReclnUpwdDnwdPosMax2.Val
          PA_KeSMSw4SAcsMd24SecRwRtStBkReclnUpwdDnwdPosMin1_Val: accessed-parameter=KeSMSw4SAcsMd24SecRwRtStBkReclnUpwdDnwdPosMin1.Val
          PA_KeSMSw4SAcsMd24SecRwRtStBkReclnUpwdDnwdPosMin2_Val: accessed-parameter=KeSMSw4SAcsMd24SecRwRtStBkReclnUpwdDnwdPosMin2.Val
          PA_KeSMSw4SAcsMd25SecRwRtStBkReclnUpwdDnwdPos_Val: accessed-parameter=KeSMSw4SAcsMd25SecRwRtStBkReclnUpwdDnwdPos.Val
          PA_KeSMSw4SAcsMd25SecRwRtStBkReclnUpwdDnwdPosMax_Val: accessed-parameter=KeSMSw4SAcsMd25SecRwRtStBkReclnUpwdDnwdPosMax.Val
          PA_KeSMSw4SAcsMd25SecRwRtStBkReclnUpwdDnwdPosMin_Val: accessed-parameter=KeSMSw4SAcsMd25SecRwRtStBkReclnUpwdDnwdPosMin.Val
          PA_KeSMSw4SAcsMd26SecRwRtStBkReclnUpwdDnwdPos_Val: accessed-parameter=KeSMSw4SAcsMd26SecRwRtStBkReclnUpwdDnwdPos.Val
          PA_KeSMSw4SAcsMd26SecRwRtStBkReclnUpwdDnwdPosMax_Val: accessed-parameter=KeSMSw4SAcsMd26SecRwRtStBkReclnUpwdDnwdPosMax.Val
          PA_KeSMSw4SAcsMd26SecRwRtStBkReclnUpwdDnwdPosMin_Val: accessed-parameter=KeSMSw4SAcsMd26SecRwRtStBkReclnUpwdDnwdPosMin.Val
          PA_KeSMSw4sLyingMDSecRwRtStBkReclnUpwdDnwdPos_Val: accessed-parameter=KeSMSw4sLyingMDSecRwRtStBkReclnUpwdDnwdPos.Val
          PA_KeSMSw4sLyingMDSecRwRtStBkReclnUpwdDnwdPosMax_Val: accessed-parameter=KeSMSw4sLyingMDSecRwRtStBkReclnUpwdDnwdPosMax.Val
          PA_KeSMSw4sLyingMDSecRwRtStBkReclnUpwdDnwdPosMin_Val: accessed-parameter=KeSMSw4sLyingMDSecRwRtStBkReclnUpwdDnwdPosMin.Val
          PA_KeSMSw4sRecoveryMDSecRwRtStBkReclnUpwdDnwdPos_Val: accessed-parameter=KeSMSw4sRecoveryMDSecRwRtStBkReclnUpwdDnwdPos.Val
          PA_KeSMSw4sRecoveryMDSecRwRtStBkReclnUpwdDnwdPosMax_Val: accessed-parameter=KeSMSw4sRecoveryMDSecRwRtStBkReclnUpwdDnwdPosMax.Val
          PA_KeSMSw4sRecoveryMDSecRwRtStBkReclnUpwdDnwdPosMin_Val: accessed-parameter=KeSMSw4sRecoveryMDSecRwRtStBkReclnUpwdDnwdPosMin.Val
          PA_KeSMSw4sVIPMDSecRwRtStBkReclnUpwdDnwdPos_Val: accessed-parameter=KeSMSw4sVIPMDSecRwRtStBkReclnUpwdDnwdPos.Val
          PA_KeSMSw4sVIPMDSecRwRtStBkReclnUpwdDnwdPosMax_Val: accessed-parameter=KeSMSw4sVIPMDSecRwRtStBkReclnUpwdDnwdPosMax.Val
          PA_KeSMSw4sVIPMDSecRwRtStBkReclnUpwdDnwdPosMin_Val: accessed-parameter=KeSMSw4sVIPMDSecRwRtStBkReclnUpwdDnwdPosMin.Val
          PA_KeSMSw6sAcsEntrySecRwRtStBkReclnUpwdDnwd1Pos_Val: accessed-parameter=KeSMSw6sAcsEntrySecRwRtStBkReclnUpwdDnwd1Pos.Val
          PA_KeSMSw6sAcsEntrySecRwRtStBkReclnUpwdDnwdPos_Val: accessed-parameter=KeSMSw6sAcsEntrySecRwRtStBkReclnUpwdDnwdPos.Val
          PA_KeSMSw6sAcsEntrySecRwRtStBkReclnUpwdDnwdPos1Max_Val: accessed-parameter=KeSMSw6sAcsEntrySecRwRtStBkReclnUpwdDnwdPos1Max.Val
          PA_KeSMSw6sAcsEntrySecRwRtStBkReclnUpwdDnwdPos1Min_Val: accessed-parameter=KeSMSw6sAcsEntrySecRwRtStBkReclnUpwdDnwdPos1Min.Val
          PA_KeSMSw6sAcsEntrySecRwRtStBkReclnUpwdDnwdPosMax_Val: accessed-parameter=KeSMSw6sAcsEntrySecRwRtStBkReclnUpwdDnwdPosMax.Val
          PA_KeSMSw6sAcsEntrySecRwRtStBkReclnUpwdDnwdPosMin_Val: accessed-parameter=KeSMSw6sAcsEntrySecRwRtStBkReclnUpwdDnwdPosMin.Val
          PA_KeSMSw6sAcsExtSecRwRtStBkReclnUpwdDnwdPos_Val: accessed-parameter=KeSMSw6sAcsExtSecRwRtStBkReclnUpwdDnwdPos.Val
          PA_KeSMSw6sAcsExtSecRwRtStBkReclnUpwdDnwdPosMax_Val: accessed-parameter=KeSMSw6sAcsExtSecRwRtStBkReclnUpwdDnwdPosMax.Val
          PA_KeSMSw6sAcsExtSecRwRtStBkReclnUpwdDnwdPosMin_Val: accessed-parameter=KeSMSw6sAcsExtSecRwRtStBkReclnUpwdDnwdPosMin.Val
          PA_KeSMSw6sRecoveryMdSecRwRtStBkReclnUpwdDnwdPos_Val: accessed-parameter=KeSMSw6sRecoveryMdSecRwRtStBkReclnUpwdDnwdPos.Val
          PA_KeSMSw6sRecoveryMdSecRwRtStBkReclnUpwdDnwdPosMax_Val: accessed-parameter=KeSMSw6sRecoveryMdSecRwRtStBkReclnUpwdDnwdPosMax.Val
          PA_KeSMSw6sRecoveryMdSecRwRtStBkReclnUpwdDnwdPosMin_Val: accessed-parameter=KeSMSw6sRecoveryMdSecRwRtStBkReclnUpwdDnwdPosMin.Val
          PA_KeSMSw6sVIPSecRwRtStBkReclnUpwdDnwdPos_Val: accessed-parameter=KeSMSw6sVIPSecRwRtStBkReclnUpwdDnwdPos.Val
          PA_KeSMSw6sVIPSecRwRtStBkReclnUpwdDnwdPosMax_Val: accessed-parameter=KeSMSw6sVIPSecRwRtStBkReclnUpwdDnwdPosMax.Val
          PA_KeSMSw6sVIPSecRwRtStBkReclnUpwdDnwdPosMin_Val: accessed-parameter=KeSMSw6sVIPSecRwRtStBkReclnUpwdDnwdPosMin.Val
          PA_KeSMSwAcsEntrySecRwRtStBkReclnUpwdDnwdPos_Val: accessed-parameter=KeSMSwAcsEntrySecRwRtStBkReclnUpwdDnwdPos.Val
          PA_KeSMSwAcsEntrySecRwRtStBkReclnUpwdDnwdPos1_Val: accessed-parameter=KeSMSwAcsEntrySecRwRtStBkReclnUpwdDnwdPos1.Val
          PA_KeSMSwAcsEntrySecRwRtStBkReclnUpwdDnwdPos1Max_Val: accessed-parameter=KeSMSwAcsEntrySecRwRtStBkReclnUpwdDnwdPos1Max.Val
          PA_KeSMSwAcsEntrySecRwRtStBkReclnUpwdDnwdPos1Min_Val: accessed-parameter=KeSMSwAcsEntrySecRwRtStBkReclnUpwdDnwdPos1Min.Val
          PA_KeSMSwAcsEntrySecRwRtStBkReclnUpwdDnwdPosMax_Val: accessed-parameter=KeSMSwAcsEntrySecRwRtStBkReclnUpwdDnwdPosMax.Val
          PA_KeSMSwAcsEntrySecRwRtStBkReclnUpwdDnwdPosMin_Val: accessed-parameter=KeSMSwAcsEntrySecRwRtStBkReclnUpwdDnwdPosMin.Val
          PA_KeSMSwAcsExtSecRwRtStBkReclnUpwdDnwdPos_Val: accessed-parameter=KeSMSwAcsExtSecRwRtStBkReclnUpwdDnwdPos.Val
          PA_KeSMSwAcsExtSecRwRtStBkReclnUpwdDnwdPosMax_Val: accessed-parameter=KeSMSwAcsExtSecRwRtStBkReclnUpwdDnwdPosMax.Val
          PA_KeSMSwAcsExtSecRwRtStBkReclnUpwdDnwdPosMin_Val: accessed-parameter=KeSMSwAcsExtSecRwRtStBkReclnUpwdDnwdPosMin.Val
          PA_KeSMSwAcsMd32SecRwRtStBkReclnUpwdDnwdPos_Val: accessed-parameter=KeSMSwAcsMd32SecRwRtStBkReclnUpwdDnwdPos.Val
          PA_KeSMSwAcsMd32SecRwRtStBkReclnUpwdDnwdPos1_Val: accessed-parameter=KeSMSwAcsMd32SecRwRtStBkReclnUpwdDnwdPos1.Val
          PA_KeSMSwAcsMd32SecRwRtStBkReclnUpwdDnwdPos1Max_Val: accessed-parameter=KeSMSwAcsMd32SecRwRtStBkReclnUpwdDnwdPos1Max.Val
          PA_KeSMSwAcsMd32SecRwRtStBkReclnUpwdDnwdPos1Min_Val: accessed-parameter=KeSMSwAcsMd32SecRwRtStBkReclnUpwdDnwdPos1Min.Val
          PA_KeSMSwAcsMd32SecRwRtStBkReclnUpwdDnwdPosMax_Val: accessed-parameter=KeSMSwAcsMd32SecRwRtStBkReclnUpwdDnwdPosMax.Val
          PA_KeSMSwAcsMd32SecRwRtStBkReclnUpwdDnwdPosMin_Val: accessed-parameter=KeSMSwAcsMd32SecRwRtStBkReclnUpwdDnwdPosMin.Val
          PA_KeSMSwAcsMd53SecRwRtStBkReclnUpwdDnwdPos_Val: accessed-parameter=KeSMSwAcsMd53SecRwRtStBkReclnUpwdDnwdPos.Val
          PA_KeSMSwAcsMd53SecRwRtStBkReclnUpwdDnwdPos1_Val: accessed-parameter=KeSMSwAcsMd53SecRwRtStBkReclnUpwdDnwdPos1.Val
          PA_KeSMSwAcsMd53SecRwRtStBkReclnUpwdDnwdPos1Max_Val: accessed-parameter=KeSMSwAcsMd53SecRwRtStBkReclnUpwdDnwdPos1Max.Val
          PA_KeSMSwAcsMd53SecRwRtStBkReclnUpwdDnwdPos1Min_Val: accessed-parameter=KeSMSwAcsMd53SecRwRtStBkReclnUpwdDnwdPos1Min.Val
          PA_KeSMSwAcsMd53SecRwRtStBkReclnUpwdDnwdPosMax_Val: accessed-parameter=KeSMSwAcsMd53SecRwRtStBkReclnUpwdDnwdPosMax.Val
          PA_KeSMSwAcsMd53SecRwRtStBkReclnUpwdDnwdPosMin_Val: accessed-parameter=KeSMSwAcsMd53SecRwRtStBkReclnUpwdDnwdPosMin.Val
          PA_KeSMSwAcsMd8SecRwRtStBkReclnUpwdDnwdPos_Val: accessed-parameter=KeSMSwAcsMd8SecRwRtStBkReclnUpwdDnwdPos.Val
          PA_KeSMSwAcsMd8SecRwRtStBkReclnUpwdDnwdPosMax_Val: accessed-parameter=KeSMSwAcsMd8SecRwRtStBkReclnUpwdDnwdPosMax.Val
          PA_KeSMSwAcsMd8SecRwRtStBkReclnUpwdDnwdPosMin_Val: accessed-parameter=KeSMSwAcsMd8SecRwRtStBkReclnUpwdDnwdPosMin.Val
          PA_KeSMSwAcsMd9SecRwRtStBkReclnUpwdDnwdPos_Val: accessed-parameter=KeSMSwAcsMd9SecRwRtStBkReclnUpwdDnwdPos.Val
          PA_KeSMSwAcsMd9SecRwRtStBkReclnUpwdDnwdPosMax_Val: accessed-parameter=KeSMSwAcsMd9SecRwRtStBkReclnUpwdDnwdPosMax.Val
          PA_KeSMSwAcsMd9SecRwRtStBkReclnUpwdDnwdPosMin_Val: accessed-parameter=KeSMSwAcsMd9SecRwRtStBkReclnUpwdDnwdPosMin.Val
          PA_KeSMSwRecoveryMdSecRwRtStBkReclnUpwdDnwdPos_Val: accessed-parameter=KeSMSwRecoveryMdSecRwRtStBkReclnUpwdDnwdPos.Val
          PA_KeSMSwRecoveryMdSecRwRtStBkReclnUpwdDnwdPosMax_Val: accessed-parameter=KeSMSwRecoveryMdSecRwRtStBkReclnUpwdDnwdPosMax.Val
          PA_KeSMSwRecoveryMdSecRwRtStBkReclnUpwdDnwdPosMin_Val: accessed-parameter=KeSMSwRecoveryMdSecRwRtStBkReclnUpwdDnwdPosMin.Val
          PA_KeSMSwVIPSecRwRtStBkReclnUpwdDnwdPos_Val: accessed-parameter=KeSMSwVIPSecRwRtStBkReclnUpwdDnwdPos.Val
          PA_KeSMSwVIPSecRwRtStBkReclnUpwdDnwdPosMax_Val: accessed-parameter=KeSMSwVIPSecRwRtStBkReclnUpwdDnwdPosMax.Val
          PA_KeSMSwVIPSecRwRtStBkReclnUpwdDnwdPosMin_Val: accessed-parameter=KeSMSwVIPSecRwRtStBkReclnUpwdDnwdPosMin.Val
  swc implementation SecRwRtStBkReclnTrgtPosSelc_Implementation: behavior=SecRwRtStBkReclnTrgtPosSelc_InternalBehavior
    code-descriptors:
      code Default: artifact-descriptors=autosar-engineering-object={short-label=Default, category=SWSRC}
package /PATAC/MSM/ModeAdjust/CalPortInterface
  16 x parameter interface:
    KeSMSw4SAcsMd23SecRwRtStBkReclnUpwdDnwdPos
      parameter data prototype Val: sw-calibration-access=READ-WRITE, type=UInt16
    KeSMSw4SAcsMd23SecRwRtStBkReclnUpwdDnwdPosMax
      parameter data prototype Val: sw-calibration-access=READ-WRITE, type=UInt16
    KeSMSw4SAcsMd23SecRwRtStBkReclnUpwdDnwdPosMin
      parameter data prototype Val: sw-calibration-access=READ-WRITE, type=UInt16
    KeSMSw4SAcsMd24SecRwRtStBkReclnUpwdDnwdPos1
      parameter data prototype Val: sw-calibration-access=READ-WRITE, type=UInt16
    KeSMSw4SAcsMd24SecRwRtStBkReclnUpwdDnwdPos1Max
      parameter data prototype Val: sw-calibration-access=READ-WRITE, type=UInt16
    KeSMSw4SAcsMd24SecRwRtStBkReclnUpwdDnwdPos1Min
      parameter data prototype Val: sw-calibration-access=READ-WRITE, type=UInt16
    KeSMSw4SAcsMd24SecRwRtStBkReclnUpwdDnwdPos2
      parameter data prototype Val: sw-calibration-access=READ-WRITE, type=UInt16
    KeSMSw4SAcsMd24SecRwRtStBkReclnUpwdDnwdPos2Max
      parameter data prototype Val: sw-calibration-access=READ-WRITE, type=UInt16
    KeSMSw4SAcsMd24SecRwRtStBkReclnUpwdDnwdPos2Min
      parameter data prototype Val: sw-calibration-access=READ-WRITE, type=UInt16
    KeSMSw4SAcsMd25SecRwRtStBkReclnUpwdDnwdPos
      parameter data prototype Val: sw-calibration-access=READ-WRITE, type=UInt16
    KeSMSw4SAcsMd25SecRwRtStBkReclnUpwdDnwdPosMax
      parameter data prototype Val: sw-calibration-access=READ-WRITE, type=UInt16
    KeSMSw4SAcsMd25SecRwRtStBkReclnUpwdDnwdPosMin
      parameter data prototype Val: sw-calibration-access=READ-WRITE, type=UInt16
    KeSMSw4SAcsMd26SecRwRtStBkReclnUpwdDnwdPos
      parameter data prototype Val: sw-calibration-access=READ-WRITE, type=UInt16
    KeSMSw4SAcsMd26SecRwRtStBkReclnUpwdDnwdPosMax
      parameter data prototype Val: sw-calibration-access=READ-WRITE, type=UInt16
    KeSMSw4SAcsMd26SecRwRtStBkReclnUpwdDnwdPosMin
      parameter data prototype Val: sw-calibration-access=READ-WRITE, type=UInt16
    Pos
      parameter data prototype Val: sw-calibration-access=READ-WRITE, type=UInt16
package /PATAC/MSM/ModeAdjust/DataType
  impl type TrgtPosCalibArray: category=ARRAY, sw-calibration-access=READ-ONLY, type-emitter=RTE  # 0:pos 1:max 2:min
    element Element: array-size=3, array-size-semantics=FIXED-SIZE, implementation-data-type=UInt16, invalid-value=0
package /PATAC/MSM/ModeAdjust/Interfaces
  sender receiver interface IfVeSMSuThdRwLtStCshnFldUpwdDnwdPos: invalidation-policy{data-element=IfVeSMSuThdRwLtStCshnFldUpwdDnwdPos/Val, handle-invalid=DONT-INVALIDATE}
    data Val: type=UInt16
  sender receiver interface IfVeSMSuThdRwRtStCshnFldUpwdDnwdPos: invalidation-policy{data-element=IfVeSMSuThdRwRtStCshnFldUpwdDnwdPos/Val, handle-invalid=DONT-INVALIDATE}
    data Val: type=UInt16
package /PATAC/MSM/ModeAdjust/PortInterface
  client server interface SecRwRtStBkReclnTrgtPosSelc
    operation Cal
  client server interface VIPR557TrgtPos
    operation Get
      5 x arg, all with type=UInt16, direction=OUT, server-argument-impl-policy=USE-ARGUMENT-TYPE:
        SecRwLtStBkReclnTrgtPos
        SecRwLtStZeroTrgtPos
        SecRwLtStLgrstUpwdDnwdTrgtPos
        SecRwLtStLgrstInwdOtwdTrgtPos
        SecRwLtStFwdBkwdTrgtPos
    operation Set
      5 x arg, all with type=UInt16, direction=IN, server-argument-impl-policy=USE-ARGUMENT-TYPE:
        SecRwLtStBkReclnTrgtPos
        SecRwLtStZeroTrgtPos
        SecRwLtStLgrstUpwdDnwdTrgtPos
        SecRwLtStLgrstInwdOtwdTrgtPos
        SecRwLtStFwdBkwdTrgtPos
  client server interface VIPRExit557TrgtPos
    operation Get
      11 x arg, all with type=UInt16, direction=OUT, server-argument-impl-policy=USE-ARGUMENT-TYPE:
        SecRwRtStBkReclnTrgtPos
        SecRwRtStZeroTrgtPos
        SecRwRtStLgrstUpwdDnwdTrgtPos
        SecRwRtStLgrstInwdOtwdTrgtPos
        ThdRwLtStBkReclnTrgtPos
        ThdRwLtStFwdBkwdTrgtPos
        ThdRwRtStBkReclnTrgtPos
        ThdRwRtStFwdBkwdTrgtPos
        PassStBkReclnTrgtPos
        PassStFwdBkwdTrgtPos
        SecRwRtStFwdBkwdTrgtPos
    operation Set
  6 x sender receiver interface:
    MdSeatOccupied: invalidation-policy{data-element=MdSeatOccupied/Val, handle-invalid=DONT-INVALIDATE}
      data Val: type=Boolean
    modestate32: invalidation-policy{data-element=modestate32/Val, handle-invalid=DONT-INVALIDATE}
      data Val: type=UInt32
    R2RBkReclinFirstStepPassFlg: invalidation-policy{data-element=R2RBkReclinFirstStepPassFlg/Val, handle-invalid=DONT-INVALIDATE}
      data Val: type=Boolean
    StgDone: invalidation-policy{data-element=StgDone/Val, handle-invalid=DONT-INVALIDATE}
      data Val: type=Boolean
    StNumFlg
      4 x data, all with type=Boolean:
        Is4s
        Is6s
        Is6s7s
        Is7s
      invalidation-policys:
        data-element=Is4s, handle-invalid=DONT-INVALIDATE
        data-element=Is6s, handle-invalid=DONT-INVALIDATE
        data-element=Is6s7s, handle-invalid=DONT-INVALIDATE
        data-element=Is7s, handle-invalid=DONT-INVALIDATE
    TrgtPosCalibArray: invalidation-policy{data-element=TrgtPosArray, handle-invalid=DONT-INVALIDATE}
      data TrgtPosArray: type=TrgtPosCalibArray  # 0:Pos 1:Max 2:Min
package /PATAC/MSM/PortInterfaces
  sender receiver interface IfVeSMSbSecRwRtStCshnFrntUpwdDnwdMovConfig: invalidation-policy{data-element=IfVeSMSbSecRwRtStCshnFrntUpwdDnwdMovConfig/Val, handle-invalid=DONT-INVALIDATE}
    data Val: type=Boolean
